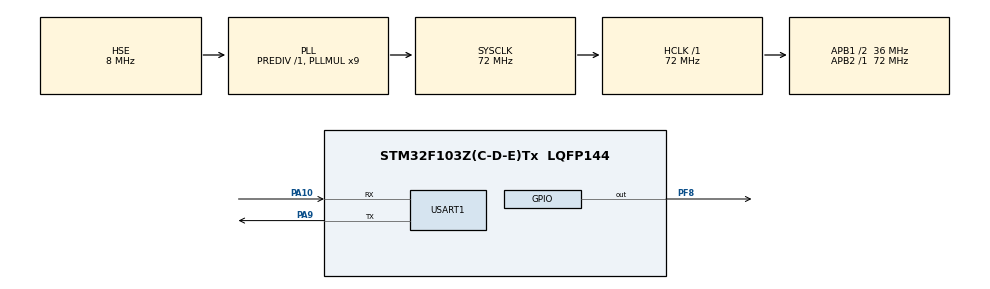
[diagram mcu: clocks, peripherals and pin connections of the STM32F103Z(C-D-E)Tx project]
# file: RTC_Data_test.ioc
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Mcu.Family=STM32F1
Mcu.Name=STM32F103Z(C-D-E)Tx
Mcu.Package=LQFP144
NVIC.PriorityGroup=NVIC_PRIORITYGROUP_4
NVIC.RTC_Alarm_IRQn=true\:0\:0\:false\:false\:true\:true\:true\:true
OSC_IN.Mode=HSE-External-Oscillator
OSC_IN.Signal=RCC_OSC_IN
OSC_OUT.Mode=HSE-External-Oscillator
OSC_OUT.Signal=RCC_OSC_OUT
PA10.Mode=Asynchronous
PA10.Signal=USART1_RX
PA13.Mode=Serial_Wire
PA13.Signal=SYS_JTMS-SWDIO
PA14.Mode=Serial_Wire
PA14.Signal=SYS_JTCK-SWCLK
PA9.Mode=Asynchronous
PA9.Signal=USART1_TX
PC14-OSC32_IN.Mode=LSE-External-Oscillator
PC14-OSC32_IN.Signal=RCC_OSC32_IN
PC15-OSC32_OUT.Mode=LSE-External-Oscillator
PC15-OSC32_OUT.Signal=RCC_OSC32_OUT
PF8.Signal=GPIO_Output
ProjectManager.HeapSize=0x200
ProjectManager.StackSize=0x400
ProjectManager.TargetToolchain=MDK-ARM V5.32
RCC.AHBFreq_Value=72000000
RCC.APB1CLKDivider=RCC_HCLK_DIV2
RCC.APB1Freq_Value=36000000
RCC.APB1TimFreq_Value=72000000
RCC.APB2Freq_Value=72000000
RCC.APB2TimFreq_Value=72000000
RCC.HCLKFreq_Value=72000000
RCC.PLLMUL=RCC_PLL_MUL9
RCC.PLLSourceVirtual=RCC_PLLSOURCE_HSE
RCC.RTCClockSelection=RCC_RTCCLKSOURCE_LSE
RCC.SYSCLKFreq_VALUE=72000000
RCC.SYSCLKSource=RCC_SYSCLKSOURCE_PLLCLK
RCC.USBFreq_Value=72000000
USART1.Parity=PARITY_ODD
USART1.VirtualMode=VM_ASYNC
USART1.WordLength=WORDLENGTH_9B
VP_RTC_VS_RTC_Activate.Mode=RTC_Enabled
board=custom

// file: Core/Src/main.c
/* USER CODE BEGIN Header */
/**
  ******************************************************************************
  * @file           : main.c
  * @brief          : Main program body
  ******************************************************************************
  * @attention
  *
  * Copyright (c) 2026 STMicroelectronics.
  * All rights reserved.
  *
  * This software is licensed under terms that can be found in the LICENSE file
  * in the root directory of this software component.
  * If no LICENSE file comes with this software, it is provided AS-IS.
  *
  ******************************************************************************
  */
/* USER CODE END Header */
#include "main.h"

/* USER CODE BEGIN Includes */
#include "BSP_Usart_Redir.h"
#include <stdbool.h>
/* USER CODE END Includes */

/* USER CODE BEGIN PD */
#define RTC_MAGICAL_NUMBER 0xABAC
/* USER CODE END PD */

/* USER CODE BEGIN PM */
volatile bool is_interrupt = false;
/* USER CODE END PM */

RTC_HandleTypeDef hrtc;

UART_HandleTypeDef huart1;

void SystemClock_Config(void);
static void MX_GPIO_Init(void);
static void MX_RTC_Init(void);
static void MX_USART1_UART_Init(void);
/* USER CODE BEGIN PFP */
void Alarm_Init_Test(void);
void GetTimeInfo(void);
void GetAlarmTimeInfo(void);
void ShowResult(void);

/* USER CODE END PFP */

int main(void)
{

  /* MCU Configuration--------------------------------------------------------*/

  /* Reset of all peripherals, Initializes the Flash interface and the Systick. */
  HAL_Init();

  /* Configure the system clock */
  SystemClock_Config();

  /* Initialize all configured peripherals */
  MX_GPIO_Init();
  MX_RTC_Init();
  MX_USART1_UART_Init();
  /* USER CODE BEGIN 2 */
  BSP_Usart_Init(&huart1);
  Alarm_Init_Test();

  //v1
  // RTC_DateTypeDef sData = {.Year  = 35,  .Month = 7,   .Date = 15};
  // RTC_TimeTypeDef sTime = {.Hours = 8, .Minutes = 0, .Seconds = 0};

  // uint16_t magic_number = HAL_RTCEx_BKUPRead(&hrtc, RTC_BKP_DR1);
  // if(magic_number != RTC_MAGICAL_NUMBER)
  // {
  //   HAL_RTCEx_BKUPWrite(&hrtc, RTC_BKP_DR1, RTC_MAGICAL_NUMBER);
  //   HAL_RTC_SetTime(&hrtc, &sTime, RTC_FORMAT_BIN);
  //   HAL_RTC_SetDate(&hrtc, &sData, RTC_FORMAT_BIN);
  //   printf("首次上电，初始化中\n");
  // }

  // RTC_TimeTypeDef outtime = { 0 };
  // RTC_DateTypeDef outdata = { 0 };
  /* USER CODE END 2 */

  /* Infinite loop */
  /* USER CODE BEGIN WHILE */
  while (1)
  {
    GetTimeInfo();
    GetAlarmTimeInfo();
    ShowResult();
    HAL_Delay(1000);
    //v1
    // HAL_RTC_GetTime(&hrtc, &outtime, RTC_FORMAT_BIN);
    // HAL_RTC_GetDate(&hrtc, &outdata, RTC_FORMAT_BIN);
    // printf(">>>time: 20%02d-%02d-%02d %02d:%02d:%02d\n",
    //   outdata.Year, outdata.Month, outdata.Date,
    //   outtime.Hours, outtime.Minutes, outtime.Seconds
    // );
    // HAL_Delay(1000);
    /* USER CODE END WHILE */

  }
}

void SystemClock_Config(void)
{
  RCC_OscInitTypeDef RCC_OscInitStruct = {0};
  RCC_ClkInitTypeDef RCC_ClkInitStruct = {0};
  RCC_PeriphCLKInitTypeDef PeriphClkInit = {0};

  /** Initializes the RCC Oscillators according to the specified parameters
  * in the RCC_OscInitTypeDef structure.
  */
  RCC_OscInitStruct.OscillatorType = RCC_OSCILLATORTYPE_HSE|RCC_OSCILLATORTYPE_LSE;
  RCC_OscInitStruct.HSEState = RCC_HSE_ON;
  RCC_OscInitStruct.HSEPredivValue = RCC_HSE_PREDIV_DIV1;
  RCC_OscInitStruct.LSEState = RCC_LSE_ON;
  RCC_OscInitStruct.HSIState = RCC_HSI_ON;
  RCC_OscInitStruct.PLL.PLLState = RCC_PLL_ON;
  RCC_OscInitStruct.PLL.PLLSource = RCC_PLLSOURCE_HSE;
  RCC_OscInitStruct.PLL.PLLMUL = RCC_PLL_MUL9;
  if (HAL_RCC_OscConfig(&RCC_OscInitStruct) != HAL_OK)
  {
    Error_Handler();
  }

  /** Initializes the CPU, AHB and APB buses clocks
  */
  RCC_ClkInitStruct.ClockType = RCC_CLOCKTYPE_HCLK|RCC_CLOCKTYPE_SYSCLK
                              |RCC_CLOCKTYPE_PCLK1|RCC_CLOCKTYPE_PCLK2;
  RCC_ClkInitStruct.SYSCLKSource = RCC_SYSCLKSOURCE_PLLCLK;
  RCC_ClkInitStruct.AHBCLKDivider = RCC_SYSCLK_DIV1;
  RCC_ClkInitStruct.APB1CLKDivider = RCC_HCLK_DIV2;
  RCC_ClkInitStruct.APB2CLKDivider = RCC_HCLK_DIV1;

  if (HAL_RCC_ClockConfig(&RCC_ClkInitStruct, FLASH_LATENCY_2) != HAL_OK)
  {
    Error_Handler();
  }
  PeriphClkInit.PeriphClockSelection = RCC_PERIPHCLK_RTC;
  PeriphClkInit.RTCClockSelection = RCC_RTCCLKSOURCE_LSE;
  if (HAL_RCCEx_PeriphCLKConfig(&PeriphClkInit) != HAL_OK)
  {
    Error_Handler();
  }
}

static void MX_RTC_Init(void)
{

  /** Initialize RTC Only
  */
  hrtc.Instance = RTC;
  hrtc.Init.AsynchPrediv = RTC_AUTO_1_SECOND;
  hrtc.Init.OutPut = RTC_OUTPUTSOURCE_ALARM;
  if (HAL_RTC_Init(&hrtc) != HAL_OK)
  {
    Error_Handler();
  }

}

static void MX_USART1_UART_Init(void)
{

  huart1.Instance = USART1;
  huart1.Init.BaudRate = 115200;
  huart1.Init.WordLength = UART_WORDLENGTH_9B;
  huart1.Init.StopBits = UART_STOPBITS_1;
  huart1.Init.Parity = UART_PARITY_ODD;
  huart1.Init.Mode = UART_MODE_TX_RX;
  huart1.Init.HwFlowCtl = UART_HWCONTROL_NONE;
  huart1.Init.OverSampling = UART_OVERSAMPLING_16;
  if (HAL_UART_Init(&huart1) != HAL_OK)
  {
    Error_Handler();
  }

}

static void MX_GPIO_Init(void)
{
  GPIO_InitTypeDef GPIO_InitStruct = {0};

  /* GPIO Ports Clock Enable */
  __HAL_RCC_GPIOC_CLK_ENABLE();
  __HAL_RCC_GPIOF_CLK_ENABLE();
  __HAL_RCC_GPIOA_CLK_ENABLE();

  /*Configure GPIO pin Output Level */
  HAL_GPIO_WritePin(GPIOF, GPIO_PIN_8, GPIO_PIN_RESET);

  /*Configure GPIO pin : PF8 */
  GPIO_InitStruct.Pin = GPIO_PIN_8;
  GPIO_InitStruct.Mode = GPIO_MODE_OUTPUT_PP;
  GPIO_InitStruct.Pull = GPIO_NOPULL;
  GPIO_InitStruct.Speed = GPIO_SPEED_FREQ_LOW;
  HAL_GPIO_Init(GPIOF, &GPIO_InitStruct);

}

/* USER CODE BEGIN 4 */
void HAL_RTC_AlarmAEventCallback(RTC_HandleTypeDef *hrtc_)
{
  if(hrtc_ == &hrtc)
  {
    is_interrupt = true;
  }
}

void Alarm_Init_Test(void)
{
  RTC_TimeTypeDef sTime = {sTime.Hours = 12, sTime.Minutes = 0, sTime.Seconds = 0};
  if(HAL_RTC_SetTime(&hrtc, &sTime, RTC_FORMAT_BIN) != HAL_OK)
  {
    Error_Handler();
  }
  //设置rtc时间
  RTC_AlarmTypeDef sAlarm = {
    sAlarm.AlarmTime.Hours = 12,
    sAlarm.AlarmTime.Minutes = 0,
    sAlarm.AlarmTime.Seconds = 10
  };
  HAL_RTC_SetAlarm_IT(&hrtc, &sAlarm, RTC_FORMAT_BIN);
  printf(">>>初始化完成\n");
}

void GetTimeInfo(void)
{
  RTC_TimeTypeDef sTime = {0};
  HAL_RTC_GetTime(&hrtc, &sTime, RTC_FORMAT_BIN);
  printf(">>>当前时间：%02d:%02d:%02d\n",sTime.Hours, sTime.Minutes, sTime.Seconds);
}

void GetAlarmTimeInfo(void)
{
  RTC_TimeTypeDef sAlarm = {0};
  HAL_RTC_GetAlarm(&hrtc, &sAlarm, RTC_ALARM_A, RTC_FORMAT_BIN);
  printf(">>>闹钟时间：%02d:%02d:%02d\n",sAlarm.Hours, sAlarm.Minutes, sAlarm.Seconds);
}

void ShowResult(void)
{
  if(is_interrupt)
  {
    is_interrupt = false;
    printf(">>>闹钟响了，处理\n");
    HAL_GPIO_WritePin(GPIOF, GPIO_PIN_8, GPIO_PIN_RESET);

  }
}

/* USER CODE END 4 */

void Error_Handler(void)
{
  __disable_irq();
  while (1)
  {
  }
}
